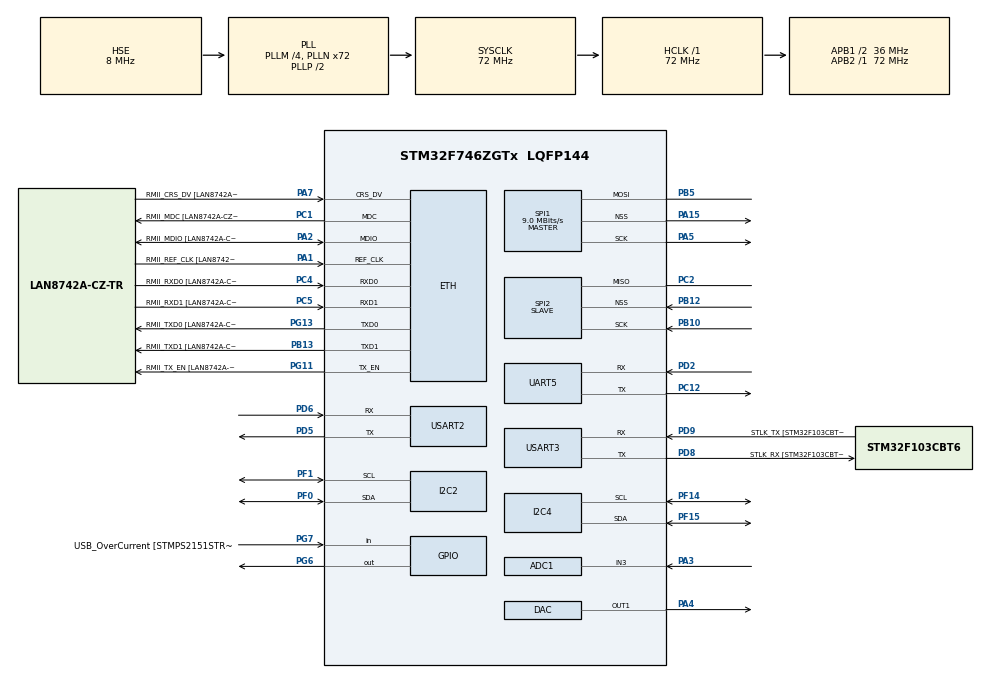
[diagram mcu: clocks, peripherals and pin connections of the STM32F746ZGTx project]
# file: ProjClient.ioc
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ADC1.Channel-0\#ChannelRegularConversion=ADC_CHANNEL_3
ADC1.ClockPrescaler=ADC_CLOCK_SYNC_PCLK_DIV2
ADC1.ContinuousConvMode=ENABLE
ADC1.DMAContinuousRequests=ENABLE
ADC1.NbrOfConversionFlag=1
ADC1.Rank-0\#ChannelRegularConversion=1
ADC1.SamplingTime-0\#ChannelRegularConversion=ADC_SAMPLETIME_3CYCLES
ADC1.master=1
CRC.OutputDataInversionMode=CRC_OUTPUTDATA_INVERSION_DISABLE
DAC.DAC_Trigger=DAC_TRIGGER_SOFTWARE
Dma.ADC1.2.Direction=DMA_PERIPH_TO_MEMORY
Dma.ADC1.2.FIFOMode=DMA_FIFOMODE_DISABLE
Dma.ADC1.2.Instance=DMA2_Stream0
Dma.ADC1.2.MemDataAlignment=DMA_MDATAALIGN_WORD
Dma.ADC1.2.MemInc=DMA_MINC_ENABLE
Dma.ADC1.2.Mode=DMA_NORMAL
Dma.ADC1.2.PeriphDataAlignment=DMA_PDATAALIGN_WORD
Dma.ADC1.2.PeriphInc=DMA_PINC_DISABLE
Dma.ADC1.2.Priority=DMA_PRIORITY_LOW
Dma.I2C2_RX.7.Direction=DMA_PERIPH_TO_MEMORY
Dma.I2C2_RX.7.FIFOMode=DMA_FIFOMODE_DISABLE
Dma.I2C2_RX.7.Instance=DMA1_Stream2
Dma.I2C2_RX.7.MemDataAlignment=DMA_MDATAALIGN_BYTE
Dma.I2C2_RX.7.MemInc=DMA_MINC_ENABLE
Dma.I2C2_RX.7.Mode=DMA_NORMAL
Dma.I2C2_RX.7.PeriphDataAlignment=DMA_PDATAALIGN_BYTE
Dma.I2C2_RX.7.PeriphInc=DMA_PINC_DISABLE
Dma.I2C2_RX.7.Priority=DMA_PRIORITY_LOW
Dma.I2C2_TX.8.Direction=DMA_MEMORY_TO_PERIPH
Dma.I2C2_TX.8.FIFOMode=DMA_FIFOMODE_DISABLE
Dma.I2C2_TX.8.Instance=DMA1_Stream7
Dma.I2C2_TX.8.MemDataAlignment=DMA_MDATAALIGN_BYTE
Dma.I2C2_TX.8.MemInc=DMA_MINC_ENABLE
Dma.I2C2_TX.8.Mode=DMA_NORMAL
Dma.I2C2_TX.8.PeriphDataAlignment=DMA_PDATAALIGN_BYTE
Dma.I2C2_TX.8.PeriphInc=DMA_PINC_DISABLE
Dma.I2C2_TX.8.Priority=DMA_PRIORITY_LOW
Dma.Request0=USART2_RX
Dma.Request1=UART5_RX
Dma.Request2=ADC1
Dma.Request3=SPI1_RX
Dma.Request4=SPI1_TX
Dma.Request5=SPI2_RX
Dma.Request6=SPI2_TX
Dma.Request7=I2C2_RX
Dma.Request8=I2C2_TX
Dma.SPI1_RX.3.Direction=DMA_PERIPH_TO_MEMORY
Dma.SPI1_RX.3.FIFOMode=DMA_FIFOMODE_DISABLE
Dma.SPI1_RX.3.Instance=DMA2_Stream2
Dma.SPI1_RX.3.MemDataAlignment=DMA_MDATAALIGN_BYTE
Dma.SPI1_RX.3.MemInc=DMA_MINC_ENABLE
Dma.SPI1_RX.3.Mode=DMA_NORMAL
Dma.SPI1_RX.3.PeriphDataAlignment=DMA_PDATAALIGN_BYTE
Dma.SPI1_RX.3.PeriphInc=DMA_PINC_DISABLE
Dma.SPI1_RX.3.Priority=DMA_PRIORITY_LOW
Dma.SPI1_TX.4.Direction=DMA_MEMORY_TO_PERIPH
Dma.SPI1_TX.4.FIFOMode=DMA_FIFOMODE_DISABLE
Dma.SPI1_TX.4.Instance=DMA2_Stream3
Dma.SPI1_TX.4.MemDataAlignment=DMA_MDATAALIGN_BYTE
Dma.SPI1_TX.4.MemInc=DMA_MINC_ENABLE
Dma.SPI1_TX.4.Mode=DMA_NORMAL
Dma.SPI1_TX.4.PeriphDataAlignment=DMA_PDATAALIGN_BYTE
Dma.SPI1_TX.4.PeriphInc=DMA_PINC_DISABLE
Dma.SPI1_TX.4.Priority=DMA_PRIORITY_LOW
Dma.SPI2_RX.5.Direction=DMA_PERIPH_TO_MEMORY
Dma.SPI2_RX.5.FIFOMode=DMA_FIFOMODE_DISABLE
Dma.SPI2_RX.5.Instance=DMA1_Stream3
Dma.SPI2_RX.5.MemDataAlignment=DMA_MDATAALIGN_BYTE
Dma.SPI2_RX.5.MemInc=DMA_MINC_ENABLE
Dma.SPI2_RX.5.Mode=DMA_NORMAL
Dma.SPI2_RX.5.PeriphDataAlignment=DMA_PDATAALIGN_BYTE
Dma.SPI2_RX.5.PeriphInc=DMA_PINC_DISABLE
Dma.SPI2_RX.5.Priority=DMA_PRIORITY_LOW
Dma.SPI2_TX.6.Direction=DMA_MEMORY_TO_PERIPH
Dma.SPI2_TX.6.FIFOMode=DMA_FIFOMODE_DISABLE
Dma.SPI2_TX.6.Instance=DMA1_Stream4
Dma.SPI2_TX.6.MemDataAlignment=DMA_MDATAALIGN_BYTE
Dma.SPI2_TX.6.MemInc=DMA_MINC_ENABLE
Dma.SPI2_TX.6.Mode=DMA_NORMAL
Dma.SPI2_TX.6.PeriphDataAlignment=DMA_PDATAALIGN_BYTE
Dma.SPI2_TX.6.PeriphInc=DMA_PINC_DISABLE
Dma.SPI2_TX.6.Priority=DMA_PRIORITY_LOW
Dma.UART5_RX.1.Direction=DMA_PERIPH_TO_MEMORY
Dma.UART5_RX.1.FIFOMode=DMA_FIFOMODE_DISABLE
Dma.UART5_RX.1.Instance=DMA1_Stream0
Dma.UART5_RX.1.MemDataAlignment=DMA_MDATAALIGN_BYTE
Dma.UART5_RX.1.MemInc=DMA_MINC_ENABLE
Dma.UART5_RX.1.Mode=DMA_CIRCULAR
Dma.UART5_RX.1.PeriphDataAlignment=DMA_PDATAALIGN_BYTE
Dma.UART5_RX.1.PeriphInc=DMA_PINC_DISABLE
Dma.UART5_RX.1.Priority=DMA_PRIORITY_LOW
Dma.USART2_RX.0.Direction=DMA_PERIPH_TO_MEMORY
Dma.USART2_RX.0.FIFOMode=DMA_FIFOMODE_DISABLE
Dma.USART2_RX.0.Instance=DMA1_Stream5
Dma.USART2_RX.0.MemDataAlignment=DMA_MDATAALIGN_BYTE
Dma.USART2_RX.0.MemInc=DMA_MINC_ENABLE
Dma.USART2_RX.0.Mode=DMA_NORMAL
Dma.USART2_RX.0.PeriphDataAlignment=DMA_PDATAALIGN_BYTE
Dma.USART2_RX.0.PeriphInc=DMA_PINC_DISABLE
Dma.USART2_RX.0.Priority=DMA_PRIORITY_LOW
ETH.MediaInterface=HAL_ETH_RMII_MODE
ETH.PHY_Name=LAN8742A_PHY_ADDRESS
ETH.PHY_Value=0
ETH.PhyAddress=0
I2C2.OwnAddress=1
I2C2.Timing=0x00808CD2
I2C4.GeneralCallMode=I2C_GENERALCALL_DISABLE
I2C4.Timing=0x00808CD2
LWIP.BSP.number=1
LWIP.IP_ADDRESS=192.168.007.002
LWIP.LWIP_DHCP=0
LWIP.NETMASK_ADDRESS=255.255.255.000
LWIP.Version=v2.1.2_Cube
LWIP0.BSP.STBoard=false
LWIP0.BSP.api=BSP_COMPONENT_DRIVER
LWIP0.BSP.component=LAN8742
LWIP0.BSP.instance=LAN8742
LWIP0.BSP.name=Driver_PHY
LWIP0.BSP.semaphore=S_LAN8742
LWIP0.BSP.solution=LAN8742
Mcu.Family=STM32F7
Mcu.Name=STM32F746ZGTx
Mcu.Package=LQFP144
NVIC.ADC_IRQn=true\:0\:0\:false\:false\:true\:true\:true\:true
NVIC.DMA1_Stream0_IRQn=true\:0\:0\:false\:false\:true\:false\:true\:true
NVIC.DMA1_Stream2_IRQn=true\:0\:0\:false\:false\:true\:false\:true\:true
NVIC.DMA1_Stream3_IRQn=true\:0\:0\:false\:false\:true\:false\:true\:true
NVIC.DMA1_Stream4_IRQn=true\:0\:0\:false\:false\:true\:false\:true\:true
NVIC.DMA1_Stream5_IRQn=true\:0\:0\:false\:false\:true\:false\:true\:true
NVIC.DMA1_Stream7_IRQn=true\:0\:0\:false\:false\:true\:false\:true\:true
NVIC.DMA2_Stream0_IRQn=true\:0\:0\:false\:false\:true\:false\:true\:true
NVIC.DMA2_Stream2_IRQn=true\:0\:0\:false\:false\:true\:false\:true\:true
NVIC.DMA2_Stream3_IRQn=true\:0\:0\:false\:false\:true\:false\:true\:true
NVIC.ETH_IRQn=true\:0\:0\:false\:false\:true\:true\:true\:true
NVIC.I2C2_ER_IRQn=true\:0\:0\:false\:false\:true\:true\:true\:true
NVIC.I2C2_EV_IRQn=true\:0\:0\:false\:false\:true\:true\:true\:true
NVIC.I2C4_ER_IRQn=true\:0\:0\:false\:false\:true\:true\:true\:true
NVIC.I2C4_EV_IRQn=true\:0\:0\:false\:false\:true\:true\:true\:true
NVIC.PriorityGroup=NVIC_PRIORITYGROUP_4
NVIC.SPI1_IRQn=true\:0\:0\:false\:false\:true\:true\:true\:true
NVIC.SPI2_IRQn=true\:1\:0\:true\:false\:true\:true\:true\:true
NVIC.TIM6_DAC_IRQn=true\:0\:0\:false\:false\:true\:true\:true\:true
NVIC.TIM7_IRQn=true\:0\:0\:false\:false\:true\:true\:true\:true
NVIC.UART5_IRQn=true\:0\:0\:false\:false\:true\:true\:true\:true
NVIC.USART2_IRQn=true\:0\:0\:false\:false\:true\:true\:true\:true
PA1.GPIO_Label=RMII_REF_CLK [LAN8742A-CZ-TR_REFCLK0]
PA1.Mode=RMII
PA1.Signal=ETH_REF_CLK
PA10.GPIO_Label=USB_ID
PA10.Signal=USB_OTG_FS_ID
PA11.GPIO_Label=USB_DM
PA11.Signal=USB_OTG_FS_DM
PA12.GPIO_Label=USB_DP
PA12.Signal=USB_OTG_FS_DP
PA13.GPIO_Label=TMS
PA13.Mode=Serial_Wire
PA13.Signal=SYS_JTMS-SWDIO
PA14.GPIO_Label=TCK
PA14.Mode=Serial_Wire
PA14.Signal=SYS_JTCK-SWCLK
PA15.GPIO_PuPd=GPIO_PULLUP
PA15.Mode=NSS_Signal_Hard_Output
PA15.Signal=SPI1_NSS
PA2.GPIO_Label=RMII_MDIO [LAN8742A-CZ-TR_MDIO]
PA2.Mode=RMII
PA2.Signal=ETH_MDIO
PA3.Signal=ADCx_IN3
PA4.Signal=COMP_DAC1_group
PA5.GPIO_Mode=GPIO_MODE_AF_PP
PA5.GPIO_PuPd=GPIO_PULLUP
PA5.Mode=Simplex_Bidirectional_Master
PA5.Signal=SPI1_SCK
PA7.GPIO_Label=RMII_CRS_DV [LAN8742A-CZ-TR_CRS_DV]
PA7.Mode=RMII
PA7.Signal=ETH_CRS_DV
PA8.GPIO_Label=USB_SOF [TP1]
PA8.Signal=USB_OTG_FS_SOF
PA9.GPIO_Label=USB_VBUS
PA9.Signal=USB_OTG_FS_VBUS
PB10.GPIO_Mode=GPIO_MODE_AF_PP
PB10.GPIO_PuPd=GPIO_PULLUP
PB10.Mode=Simplex_Bidirectional_Slave
PB10.Signal=SPI2_SCK
PB12.GPIO_Mode=GPIO_MODE_AF_PP
PB12.GPIO_PuPd=GPIO_PULLUP
PB12.Mode=NSS_Signal_Hard_Input
PB12.Signal=SPI2_NSS
PB13.GPIO_Label=RMII_TXD1 [LAN8742A-CZ-TR_TXD1]
PB13.Mode=RMII
PB13.Signal=ETH_TXD1
PB3.GPIO_Label=SW0
PB3.Signal=SYS_JTDO-SWO
PB5.GPIO_PuPd=GPIO_PULLUP
PB5.Mode=Simplex_Bidirectional_Master
PB5.Signal=SPI1_MOSI
PC1.GPIO_Label=RMII_MDC [LAN8742A-CZ-TR_MDC]
PC1.Mode=RMII
PC1.Signal=ETH_MDC
PC12.GPIO_PuPd=GPIO_PULLUP
PC12.Mode=Asynchronous
PC12.Signal=UART5_TX
PC14/OSC32_IN.Mode=LSE-External-Oscillator
PC14/OSC32_IN.Signal=RCC_OSC32_IN
PC15/OSC32_OUT.Mode=LSE-External-Oscillator
PC15/OSC32_OUT.Signal=RCC_OSC32_OUT
PC2.GPIO_Mode=GPIO_MODE_AF_PP
PC2.GPIO_PuPd=GPIO_PULLUP
PC2.Mode=Simplex_Bidirectional_Slave
PC2.Signal=SPI2_MISO
PC4.GPIO_Label=RMII_RXD0 [LAN8742A-CZ-TR_RXD0]
PC4.Mode=RMII
PC4.Signal=ETH_RXD0
PC5.GPIO_Label=RMII_RXD1 [LAN8742A-CZ-TR_RXD1]
PC5.Mode=RMII
PC5.Signal=ETH_RXD1
PD2.GPIO_PuPd=GPIO_PULLUP
PD2.Mode=Asynchronous
PD2.Signal=UART5_RX
PD5.GPIO_ModeDefaultPP=GPIO_MODE_AF_PP
PD5.GPIO_PuPd=GPIO_PULLUP
PD5.Mode=Asynchronous
PD5.Signal=USART2_TX
PD6.GPIO_ModeDefaultPP=GPIO_MODE_AF_PP
PD6.GPIO_PuPd=GPIO_PULLUP
PD6.Mode=Asynchronous
PD6.Signal=USART2_RX
PD8.GPIO_Label=STLK_RX [STM32F103CBT6_PA3]
PD8.GPIO_PuPd=GPIO_PULLUP
PD8.Mode=Asynchronous
PD8.Signal=USART3_TX
PD9.GPIO_Label=STLK_TX [STM32F103CBT6_PA2]
PD9.GPIO_PuPd=GPIO_PULLUP
PD9.Mode=Asynchronous
PD9.Signal=USART3_RX
PF0.GPIO_Pu=GPIO_PULLUP
PF0.Mode=I2C
PF0.Signal=I2C2_SDA
PF1.GPIO_Mode=GPIO_MODE_AF_OD
PF1.GPIO_Pu=GPIO_PULLUP
PF1.Mode=I2C
PF1.Signal=I2C2_SCL
PF14.GPIO_Pu=GPIO_PULLUP
PF14.Mode=I2C
PF14.Signal=I2C4_SCL
PF15.GPIO_Pu=GPIO_PULLUP
PF15.Mode=I2C
PF15.Signal=I2C4_SDA
PG11.GPIO_Label=RMII_TX_EN [LAN8742A-CZ-TR_TXEN]
PG11.Mode=RMII
PG11.Signal=ETH_TX_EN
PG13.GPIO_Label=RMII_TXD0 [LAN8742A-CZ-TR_TXD0]
PG13.Mode=RMII
PG13.Signal=ETH_TXD0
PG6.Signal=GPIO_Output
PG7.GPIO_Label=USB_OverCurrent [STMPS2151STR_FAULT]
PG7.Signal=GPIO_Input
PH0/OSC_IN.GPIO_Label=MCO [STM32F103CBT6_PA8]
PH0/OSC_IN.Mode=HSE-External-Clock-Source
PH0/OSC_IN.Signal=RCC_OSC_IN
PH1/OSC_OUT.Mode=HSE-External-Clock-Source
PH1/OSC_OUT.Signal=RCC_OSC_OUT
ProjectManager.HeapSize=0x200
ProjectManager.StackSize=0x400
ProjectManager.TargetToolchain=STM32CubeIDE
RCC.48MHZClocksFreq_Value=24000000
RCC.AHBFreq_Value=72000000
RCC.APB1CLKDivider=RCC_HCLK_DIV2
RCC.APB1Freq_Value=36000000
RCC.APB1TimFreq_Value=72000000
RCC.APB2Freq_Value=72000000
RCC.APB2TimFreq_Value=72000000
RCC.CortexFreq_Value=72000000
RCC.HCLKFreq_Value=72000000
RCC.HSE_VALUE=8000000
RCC.HSI_VALUE=16000000
RCC.PLLM=4
RCC.PLLMUL=RCC_PLL_MUL9
RCC.PLLN=72
RCC.PLLQ=3
RCC.PLLSourceVirtual=RCC_PLLSOURCE_HSE
RCC.PRESCALERUSB=RCC_USBCLKSOURCE_PLL_DIV1_5
RCC.SYSCLKFreq_VALUE=72000000
RCC.SYSCLKSource=RCC_SYSCLKSOURCE_PLLCLK
RCC.SYSCLKSourceVirtual=RCC_SYSCLKSOURCE_PLLCLK
RCC.USBFreq_Value=48000000
RCC.VCOOutputFreq_Value=144000000
SH.ADCx_IN3.0=ADC1_IN3,IN3
SH.COMP_DAC1_group.0=DAC_OUT1,DAC_OUT1
SPI1.BaudRatePrescaler=SPI_BAUDRATEPRESCALER_8
SPI1.CRCCalculation=SPI_CRCCALCULATION_DISABLE
SPI1.CalculateBaudRate=9.0 MBits/s
SPI1.DataSize=SPI_DATASIZE_8BIT
SPI1.Direction=SPI_DIRECTION_1LINE
SPI1.Mode=SPI_MODE_MASTER
SPI1.NSSPMode=SPI_NSS_PULSE_ENABLE
SPI1.VirtualNSS=VM_NSSHARD
SPI1.VirtualType=VM_MASTER
SPI2.DataSize=SPI_DATASIZE_8BIT
SPI2.Direction=SPI_DIRECTION_1LINE
SPI2.Mode=SPI_MODE_SLAVE
SPI2.VirtualNSS=VM_NSSHARD
SPI2.VirtualType=VM_SLAVE
TIM7.AutoReloadPreload=TIM_AUTORELOAD_PRELOAD_ENABLE
TIM7.Prescaler=36000-1
USART2.VirtualMode-Asynchronous=VM_ASYNC
USART3.VirtualMode-Asynchronous=VM_ASYNC
VP_CRC_VS_CRC.Mode=CRC_Activate
VP_LWIP_VS_Enabled.Mode=Enabled
VP_RTC_VS_RTC_Activate.Mode=RTC_Enabled
VP_RTC_VS_RTC_Calendar.Mode=RTC_Calendar
VP_RTC_VS_RTC_WakeUp_intern.Mode=WakeUp
VP_TIM7_VS_ClockSourceINT.Mode=Enable_Timer
board=NUCLEO-F746ZG

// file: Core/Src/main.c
/* USER CODE BEGIN Header */
/**
  ******************************************************************************
  * @file           : main.c
  * @brief          : Main program body
  ******************************************************************************
  * @attention
  *
  * Copyright (c) 2023 STMicroelectronics.
  * All rights reserved.
  *
  * This software is licensed under terms that can be found in the LICENSE file
  * in the root directory of this software component.
  * If no LICENSE file comes with this software, it is provided AS-IS.
  *
  ******************************************************************************
  */
/* USER CODE END Header */
#include "main.h"
#include "lwip.h"

/* USER CODE BEGIN Includes */
#include "Testing_Program.h"
#include "timer_testing.h"
#include "uart.h"
#include "adc_testing.h"
#include "spi_testing.h"
#include "i2c_testing.h"
/* USER CODE END Includes */

/* USER CODE BEGIN PD */
//#define BUFF_SIZE 1024
/* USER CODE END PD */

ADC_HandleTypeDef hadc1;
DMA_HandleTypeDef hdma_adc1;

CRC_HandleTypeDef hcrc;

DAC_HandleTypeDef hdac;

I2C_HandleTypeDef hi2c2;
I2C_HandleTypeDef hi2c4;
DMA_HandleTypeDef hdma_i2c2_rx;
DMA_HandleTypeDef hdma_i2c2_tx;

RTC_HandleTypeDef hrtc;

SPI_HandleTypeDef hspi1;
SPI_HandleTypeDef hspi2;
DMA_HandleTypeDef hdma_spi1_rx;
DMA_HandleTypeDef hdma_spi1_tx;
DMA_HandleTypeDef hdma_spi2_rx;
DMA_HandleTypeDef hdma_spi2_tx;

TIM_HandleTypeDef htim7;

UART_HandleTypeDef huart5;
UART_HandleTypeDef huart2;
UART_HandleTypeDef huart3;
DMA_HandleTypeDef hdma_uart5_rx;
DMA_HandleTypeDef hdma_usart2_rx;

void SystemClock_Config(void);
static void MX_GPIO_Init(void);
static void MX_DMA_Init(void);
static void MX_USART3_UART_Init(void);
static void MX_USART2_UART_Init(void);
static void MX_SPI1_Init(void);
static void MX_I2C2_Init(void);
static void MX_DAC_Init(void);
static void MX_I2C4_Init(void);
static void MX_UART5_Init(void);
static void MX_CRC_Init(void);
static void MX_ADC1_Init(void);
static void MX_TIM7_Init(void);
static void MX_SPI2_Init(void);
static void MX_RTC_Init(void);

/* USER CODE BEGIN 0 */
extern struct netif gnetif;
/* USER CODE END 0 */

int main(void)
{

  /* MCU Configuration--------------------------------------------------------*/

  /* Reset of all peripherals, Initializes the Flash interface and the Systick. */
  HAL_Init();

  /* Configure the system clock */
  SystemClock_Config();

  /* Initialize all configured peripherals */
  MX_GPIO_Init();
  MX_DMA_Init();
  MX_USART3_UART_Init();
  MX_USART2_UART_Init();
  MX_SPI1_Init();
  MX_I2C2_Init();
  MX_DAC_Init();
  MX_I2C4_Init();
  MX_UART5_Init();
  MX_LWIP_Init();
  MX_CRC_Init();
  MX_ADC1_Init();
  MX_TIM7_Init();
  MX_SPI2_Init();
  MX_RTC_Init();

  /* Infinite loop */
  /* USER CODE BEGIN WHILE */
  while (1)
  {
	  Testing_Program();

  }
    /* USER CODE END WHILE */

}

void SystemClock_Config(void)
{
  RCC_OscInitTypeDef RCC_OscInitStruct = {0};
  RCC_ClkInitTypeDef RCC_ClkInitStruct = {0};

  /** Configure LSE Drive Capability
  */
  HAL_PWR_EnableBkUpAccess();

  /** Configure the main internal regulator output voltage
  */
  __HAL_RCC_PWR_CLK_ENABLE();
  __HAL_PWR_VOLTAGESCALING_CONFIG(PWR_REGULATOR_VOLTAGE_SCALE3);

  /** Initializes the RCC Oscillators according to the specified parameters
  * in the RCC_OscInitTypeDef structure.
  */
  RCC_OscInitStruct.OscillatorType = RCC_OSCILLATORTYPE_LSI|RCC_OSCILLATORTYPE_HSE;
  RCC_OscInitStruct.HSEState = RCC_HSE_BYPASS;
  RCC_OscInitStruct.LSIState = RCC_LSI_ON;
  RCC_OscInitStruct.PLL.PLLState = RCC_PLL_ON;
  RCC_OscInitStruct.PLL.PLLSource = RCC_PLLSOURCE_HSE;
  RCC_OscInitStruct.PLL.PLLM = 4;
  RCC_OscInitStruct.PLL.PLLN = 72;
  RCC_OscInitStruct.PLL.PLLP = RCC_PLLP_DIV2;
  RCC_OscInitStruct.PLL.PLLQ = 3;
  if (HAL_RCC_OscConfig(&RCC_OscInitStruct) != HAL_OK)
  {
    Error_Handler();
  }

  /** Initializes the CPU, AHB and APB buses clocks
  */
  RCC_ClkInitStruct.ClockType = RCC_CLOCKTYPE_HCLK|RCC_CLOCKTYPE_SYSCLK
                              |RCC_CLOCKTYPE_PCLK1|RCC_CLOCKTYPE_PCLK2;
  RCC_ClkInitStruct.SYSCLKSource = RCC_SYSCLKSOURCE_PLLCLK;
  RCC_ClkInitStruct.AHBCLKDivider = RCC_SYSCLK_DIV1;
  RCC_ClkInitStruct.APB1CLKDivider = RCC_HCLK_DIV2;
  RCC_ClkInitStruct.APB2CLKDivider = RCC_HCLK_DIV1;

  if (HAL_RCC_ClockConfig(&RCC_ClkInitStruct, FLASH_LATENCY_2) != HAL_OK)
  {
    Error_Handler();
  }
}

static void MX_ADC1_Init(void)
{

  ADC_ChannelConfTypeDef sConfig = {0};

  /** Configure the global features of the ADC (Clock, Resolution, Data Alignment and number of conversion)
  */
  hadc1.Instance = ADC1;
  hadc1.Init.ClockPrescaler = ADC_CLOCK_SYNC_PCLK_DIV2;
  hadc1.Init.Resolution = ADC_RESOLUTION_12B;
  hadc1.Init.ScanConvMode = ADC_SCAN_DISABLE;
  hadc1.Init.ContinuousConvMode = ENABLE;
  hadc1.Init.DiscontinuousConvMode = DISABLE;
  hadc1.Init.ExternalTrigConvEdge = ADC_EXTERNALTRIGCONVEDGE_NONE;
  hadc1.Init.ExternalTrigConv = ADC_SOFTWARE_START;
  hadc1.Init.DataAlign = ADC_DATAALIGN_RIGHT;
  hadc1.Init.NbrOfConversion = 1;
  hadc1.Init.DMAContinuousRequests = ENABLE;
  hadc1.Init.EOCSelection = ADC_EOC_SINGLE_CONV;
  if (HAL_ADC_Init(&hadc1) != HAL_OK)
  {
    Error_Handler();
  }

  /** Configure for the selected ADC regular channel its corresponding rank in the sequencer and its sample time.
  */
  sConfig.Channel = ADC_CHANNEL_3;
  sConfig.Rank = ADC_REGULAR_RANK_1;
  sConfig.SamplingTime = ADC_SAMPLETIME_3CYCLES;
  if (HAL_ADC_ConfigChannel(&hadc1, &sConfig) != HAL_OK)
  {
    Error_Handler();
  }

}

static void MX_CRC_Init(void)
{

  hcrc.Instance = CRC;
  hcrc.Init.DefaultPolynomialUse = DEFAULT_POLYNOMIAL_ENABLE;
  hcrc.Init.DefaultInitValueUse = DEFAULT_INIT_VALUE_ENABLE;
  hcrc.Init.InputDataInversionMode = CRC_INPUTDATA_INVERSION_NONE;
  hcrc.Init.OutputDataInversionMode = CRC_OUTPUTDATA_INVERSION_DISABLE;
  hcrc.InputDataFormat = CRC_INPUTDATA_FORMAT_BYTES;
  if (HAL_CRC_Init(&hcrc) != HAL_OK)
  {
    Error_Handler();
  }

}

static void MX_DAC_Init(void)
{

  DAC_ChannelConfTypeDef sConfig = {0};

  /** DAC Initialization
  */
  hdac.Instance = DAC;
  if (HAL_DAC_Init(&hdac) != HAL_OK)
  {
    Error_Handler();
  }

  /** DAC channel OUT1 config
  */
  sConfig.DAC_Trigger = DAC_TRIGGER_SOFTWARE;
  sConfig.DAC_OutputBuffer = DAC_OUTPUTBUFFER_ENABLE;
  if (HAL_DAC_ConfigChannel(&hdac, &sConfig, DAC_CHANNEL_1) != HAL_OK)
  {
    Error_Handler();
  }

}

static void MX_I2C2_Init(void)
{

  hi2c2.Instance = I2C2;
  hi2c2.Init.Timing = 0x00808CD2;
  hi2c2.Init.OwnAddress1 = 2;
  hi2c2.Init.AddressingMode = I2C_ADDRESSINGMODE_7BIT;
  hi2c2.Init.DualAddressMode = I2C_DUALADDRESS_DISABLE;
  hi2c2.Init.OwnAddress2 = 0;
  hi2c2.Init.OwnAddress2Masks = I2C_OA2_NOMASK;
  hi2c2.Init.GeneralCallMode = I2C_GENERALCALL_DISABLE;
  hi2c2.Init.NoStretchMode = I2C_NOSTRETCH_DISABLE;
  if (HAL_I2C_Init(&hi2c2) != HAL_OK)
  {
    Error_Handler();
  }

  /** Configure Analogue filter
  */
  if (HAL_I2CEx_ConfigAnalogFilter(&hi2c2, I2C_ANALOGFILTER_ENABLE) != HAL_OK)
  {
    Error_Handler();
  }

  /** Configure Digital filter
  */
  if (HAL_I2CEx_ConfigDigitalFilter(&hi2c2, 0) != HAL_OK)
  {
    Error_Handler();
  }

}

static void MX_I2C4_Init(void)
{

  hi2c4.Instance = I2C4;
  hi2c4.Init.Timing = 0x00808CD2;
  hi2c4.Init.OwnAddress1 = 0;
  hi2c4.Init.AddressingMode = I2C_ADDRESSINGMODE_7BIT;
  hi2c4.Init.DualAddressMode = I2C_DUALADDRESS_DISABLE;
  hi2c4.Init.OwnAddress2 = 0;
  hi2c4.Init.OwnAddress2Masks = I2C_OA2_NOMASK;
  hi2c4.Init.GeneralCallMode = I2C_GENERALCALL_DISABLE;
  hi2c4.Init.NoStretchMode = I2C_NOSTRETCH_DISABLE;
  if (HAL_I2C_Init(&hi2c4) != HAL_OK)
  {
    Error_Handler();
  }

  /** Configure Analogue filter
  */
  if (HAL_I2CEx_ConfigAnalogFilter(&hi2c4, I2C_ANALOGFILTER_ENABLE) != HAL_OK)
  {
    Error_Handler();
  }

  /** Configure Digital filter
  */
  if (HAL_I2CEx_ConfigDigitalFilter(&hi2c4, 0) != HAL_OK)
  {
    Error_Handler();
  }

}

static void MX_RTC_Init(void)
{

  RTC_TimeTypeDef sTime = {0};
  RTC_DateTypeDef sDate = {0};

  /** Initialize RTC Only
  */
  hrtc.Instance = RTC;
  hrtc.Init.HourFormat = RTC_HOURFORMAT_24;
  hrtc.Init.AsynchPrediv = 127;
  hrtc.Init.SynchPrediv = 255;
  hrtc.Init.OutPut = RTC_OUTPUT_DISABLE;
  hrtc.Init.OutPutPolarity = RTC_OUTPUT_POLARITY_HIGH;
  hrtc.Init.OutPutType = RTC_OUTPUT_TYPE_OPENDRAIN;
  if (HAL_RTC_Init(&hrtc) != HAL_OK)
  {
    Error_Handler();
  }

  /** Initialize RTC and set the Time and Date
  */
  sTime.Hours = 0x0;
  sTime.Minutes = 0x0;
  sTime.Seconds = 0x0;
  sTime.DayLightSaving = RTC_DAYLIGHTSAVING_NONE;
  sTime.StoreOperation = RTC_STOREOPERATION_RESET;
  if (HAL_RTC_SetTime(&hrtc, &sTime, RTC_FORMAT_BCD) != HAL_OK)
  {
    Error_Handler();
  }
  sDate.WeekDay = RTC_WEEKDAY_MONDAY;
  sDate.Month = RTC_MONTH_JANUARY;
  sDate.Date = 0x1;
  sDate.Year = 0x0;

  if (HAL_RTC_SetDate(&hrtc, &sDate, RTC_FORMAT_BCD) != HAL_OK)
  {
    Error_Handler();
  }

  /** Enable the WakeUp
  */
  if (HAL_RTCEx_SetWakeUpTimer(&hrtc, 0, RTC_WAKEUPCLOCK_RTCCLK_DIV16) != HAL_OK)
  {
    Error_Handler();
  }

}

static void MX_SPI1_Init(void)
{

  /* SPI1 parameter configuration*/
  hspi1.Instance = SPI1;
  hspi1.Init.Mode = SPI_MODE_MASTER;
  hspi1.Init.Direction = SPI_DIRECTION_1LINE;
  hspi1.Init.DataSize = SPI_DATASIZE_8BIT;
  hspi1.Init.CLKPolarity = SPI_POLARITY_LOW;
  hspi1.Init.CLKPhase = SPI_PHASE_1EDGE;
  hspi1.Init.NSS = SPI_NSS_HARD_OUTPUT;
  hspi1.Init.BaudRatePrescaler = SPI_BAUDRATEPRESCALER_8;
  hspi1.Init.FirstBit = SPI_FIRSTBIT_MSB;
  hspi1.Init.TIMode = SPI_TIMODE_DISABLE;
  hspi1.Init.CRCCalculation = SPI_CRCCALCULATION_DISABLE;
  hspi1.Init.CRCPolynomial = 7;
  hspi1.Init.CRCLength = SPI_CRC_LENGTH_DATASIZE;
  hspi1.Init.NSSPMode = SPI_NSS_PULSE_ENABLE;
  if (HAL_SPI_Init(&hspi1) != HAL_OK)
  {
    Error_Handler();
  }

}

static void MX_SPI2_Init(void)
{

  /* SPI2 parameter configuration*/
  hspi2.Instance = SPI2;
  hspi2.Init.Mode = SPI_MODE_SLAVE;
  hspi2.Init.Direction = SPI_DIRECTION_1LINE;
  hspi2.Init.DataSize = SPI_DATASIZE_8BIT;
  hspi2.Init.CLKPolarity = SPI_POLARITY_LOW;
  hspi2.Init.CLKPhase = SPI_PHASE_1EDGE;
  hspi2.Init.NSS = SPI_NSS_HARD_INPUT;
  hspi2.Init.FirstBit = SPI_FIRSTBIT_MSB;
  hspi2.Init.TIMode = SPI_TIMODE_DISABLE;
  hspi2.Init.CRCCalculation = SPI_CRCCALCULATION_DISABLE;
  hspi2.Init.CRCPolynomial = 7;
  hspi2.Init.CRCLength = SPI_CRC_LENGTH_DATASIZE;
  hspi2.Init.NSSPMode = SPI_NSS_PULSE_DISABLE;
  if (HAL_SPI_Init(&hspi2) != HAL_OK)
  {
    Error_Handler();
  }

}

static void MX_TIM7_Init(void)
{

  TIM_MasterConfigTypeDef sMasterConfig = {0};

  htim7.Instance = TIM7;
  htim7.Init.Prescaler = 36000-1;
  htim7.Init.CounterMode = TIM_COUNTERMODE_UP;
  htim7.Init.Period = 65535;
  htim7.Init.AutoReloadPreload = TIM_AUTORELOAD_PRELOAD_ENABLE;
  if (HAL_TIM_Base_Init(&htim7) != HAL_OK)
  {
    Error_Handler();
  }
  sMasterConfig.MasterOutputTrigger = TIM_TRGO_RESET;
  sMasterConfig.MasterSlaveMode = TIM_MASTERSLAVEMODE_DISABLE;
  if (HAL_TIMEx_MasterConfigSynchronization(&htim7, &sMasterConfig) != HAL_OK)
  {
    Error_Handler();
  }

}

static void MX_UART5_Init(void)
{

  huart5.Instance = UART5;
  huart5.Init.BaudRate = 115200;
  huart5.Init.WordLength = UART_WORDLENGTH_8B;
  huart5.Init.StopBits = UART_STOPBITS_1;
  huart5.Init.Parity = UART_PARITY_NONE;
  huart5.Init.Mode = UART_MODE_TX_RX;
  huart5.Init.HwFlowCtl = UART_HWCONTROL_NONE;
  huart5.Init.OverSampling = UART_OVERSAMPLING_16;
  huart5.Init.OneBitSampling = UART_ONE_BIT_SAMPLE_DISABLE;
  huart5.AdvancedInit.AdvFeatureInit = UART_ADVFEATURE_NO_INIT;
  if (HAL_UART_Init(&huart5) != HAL_OK)
  {
    Error_Handler();
  }

}

static void MX_USART2_UART_Init(void)
{

  huart2.Instance = USART2;
  huart2.Init.BaudRate = 115200;
  huart2.Init.WordLength = UART_WORDLENGTH_8B;
  huart2.Init.StopBits = UART_STOPBITS_1;
  huart2.Init.Parity = UART_PARITY_NONE;
  huart2.Init.Mode = UART_MODE_TX_RX;
  huart2.Init.HwFlowCtl = UART_HWCONTROL_NONE;
  huart2.Init.OverSampling = UART_OVERSAMPLING_16;
  huart2.Init.OneBitSampling = UART_ONE_BIT_SAMPLE_DISABLE;
  huart2.AdvancedInit.AdvFeatureInit = UART_ADVFEATURE_NO_INIT;
  if (HAL_UART_Init(&huart2) != HAL_OK)
  {
    Error_Handler();
  }

}

static void MX_USART3_UART_Init(void)
{

  huart3.Instance = USART3;
  huart3.Init.BaudRate = 115200;
  huart3.Init.WordLength = UART_WORDLENGTH_8B;
  huart3.Init.StopBits = UART_STOPBITS_1;
  huart3.Init.Parity = UART_PARITY_NONE;
  huart3.Init.Mode = UART_MODE_TX_RX;
  huart3.Init.HwFlowCtl = UART_HWCONTROL_NONE;
  huart3.Init.OverSampling = UART_OVERSAMPLING_16;
  huart3.Init.OneBitSampling = UART_ONE_BIT_SAMPLE_DISABLE;
  huart3.AdvancedInit.AdvFeatureInit = UART_ADVFEATURE_NO_INIT;
  if (HAL_UART_Init(&huart3) != HAL_OK)
  {
    Error_Handler();
  }

}

static void MX_DMA_Init(void)
{

  /* DMA controller clock enable */
  __HAL_RCC_DMA1_CLK_ENABLE();
  __HAL_RCC_DMA2_CLK_ENABLE();

  /* DMA interrupt init */
  /* DMA1_Stream0_IRQn interrupt configuration */
  HAL_NVIC_SetPriority(DMA1_Stream0_IRQn, 0, 0);
  HAL_NVIC_EnableIRQ(DMA1_Stream0_IRQn);
  /* DMA1_Stream2_IRQn interrupt configuration */
  HAL_NVIC_SetPriority(DMA1_Stream2_IRQn, 0, 0);
  HAL_NVIC_EnableIRQ(DMA1_Stream2_IRQn);
  /* DMA1_Stream3_IRQn interrupt configuration */
  HAL_NVIC_SetPriority(DMA1_Stream3_IRQn, 0, 0);
  HAL_NVIC_EnableIRQ(DMA1_Stream3_IRQn);
  /* DMA1_Stream4_IRQn interrupt configuration */
  HAL_NVIC_SetPriority(DMA1_Stream4_IRQn, 0, 0);
  HAL_NVIC_EnableIRQ(DMA1_Stream4_IRQn);
  /* DMA1_Stream5_IRQn interrupt configuration */
  HAL_NVIC_SetPriority(DMA1_Stream5_IRQn, 0, 0);
  HAL_NVIC_EnableIRQ(DMA1_Stream5_IRQn);
  /* DMA1_Stream7_IRQn interrupt configuration */
  HAL_NVIC_SetPriority(DMA1_Stream7_IRQn, 0, 0);
  HAL_NVIC_EnableIRQ(DMA1_Stream7_IRQn);
  /* DMA2_Stream0_IRQn interrupt configuration */
  HAL_NVIC_SetPriority(DMA2_Stream0_IRQn, 0, 0);
  HAL_NVIC_EnableIRQ(DMA2_Stream0_IRQn);
  /* DMA2_Stream2_IRQn interrupt configuration */
  HAL_NVIC_SetPriority(DMA2_Stream2_IRQn, 0, 0);
  HAL_NVIC_EnableIRQ(DMA2_Stream2_IRQn);
  /* DMA2_Stream3_IRQn interrupt configuration */
  HAL_NVIC_SetPriority(DMA2_Stream3_IRQn, 0, 0);
  HAL_NVIC_EnableIRQ(DMA2_Stream3_IRQn);

}

static void MX_GPIO_Init(void)
{
  GPIO_InitTypeDef GPIO_InitStruct = {0};

  /* GPIO Ports Clock Enable */
  __HAL_RCC_GPIOC_CLK_ENABLE();
  __HAL_RCC_GPIOF_CLK_ENABLE();
  __HAL_RCC_GPIOH_CLK_ENABLE();
  __HAL_RCC_GPIOA_CLK_ENABLE();
  __HAL_RCC_GPIOB_CLK_ENABLE();
  __HAL_RCC_GPIOD_CLK_ENABLE();
  __HAL_RCC_GPIOG_CLK_ENABLE();

  /*Configure GPIO pin Output Level */
  HAL_GPIO_WritePin(GPIOG, GPIO_PIN_6, GPIO_PIN_RESET);

  /*Configure GPIO pin : PG6 */
  GPIO_InitStruct.Pin = GPIO_PIN_6;
  GPIO_InitStruct.Mode = GPIO_MODE_OUTPUT_PP;
  GPIO_InitStruct.Pull = GPIO_NOPULL;
  GPIO_InitStruct.Speed = GPIO_SPEED_FREQ_LOW;
  HAL_GPIO_Init(GPIOG, &GPIO_InitStruct);

  /*Configure GPIO pin : USB_OverCurrent_Pin */
  GPIO_InitStruct.Pin = USB_OverCurrent_Pin;
  GPIO_InitStruct.Mode = GPIO_MODE_INPUT;
  GPIO_InitStruct.Pull = GPIO_NOPULL;
  HAL_GPIO_Init(USB_OverCurrent_GPIO_Port, &GPIO_InitStruct);

  /*Configure GPIO pins : USB_SOF_Pin USB_ID_Pin USB_DM_Pin USB_DP_Pin */
  GPIO_InitStruct.Pin = USB_SOF_Pin|USB_ID_Pin|USB_DM_Pin|USB_DP_Pin;
  GPIO_InitStruct.Mode = GPIO_MODE_AF_PP;
  GPIO_InitStruct.Pull = GPIO_NOPULL;
  GPIO_InitStruct.Speed = GPIO_SPEED_FREQ_VERY_HIGH;
  GPIO_InitStruct.Alternate = GPIO_AF10_OTG_FS;
  HAL_GPIO_Init(GPIOA, &GPIO_InitStruct);

  /*Configure GPIO pin : USB_VBUS_Pin */
  GPIO_InitStruct.Pin = USB_VBUS_Pin;
  GPIO_InitStruct.Mode = GPIO_MODE_INPUT;
  GPIO_InitStruct.Pull = GPIO_NOPULL;
  HAL_GPIO_Init(USB_VBUS_GPIO_Port, &GPIO_InitStruct);

}

void Error_Handler(void)
{
  __disable_irq();
  while (1)
  {
  }
}
